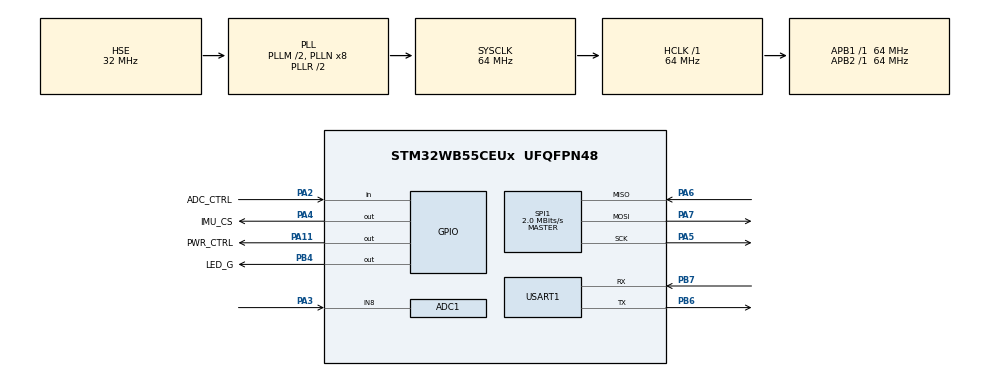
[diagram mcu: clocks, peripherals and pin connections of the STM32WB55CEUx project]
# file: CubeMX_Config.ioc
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ADC1.Channel-0\#ChannelRegularConversion=ADC_CHANNEL_8
ADC1.Channel-3\#ChannelRegularConversion=ADC_CHANNEL_VBAT
ADC1.Channel-4\#ChannelRegularConversion=ADC_CHANNEL_VREFINT
ADC1.ClockPrescaler=ADC_CLOCK_SYNC_PCLK_DIV4
ADC1.EOCSelection=ADC_EOC_SINGLE_CONV
ADC1.NbrOfConversion=3
ADC1.NbrOfConversionFlag=1
ADC1.OffsetNumber-0\#ChannelRegularConversion=ADC_OFFSET_NONE
ADC1.OffsetNumber-3\#ChannelRegularConversion=ADC_OFFSET_NONE
ADC1.OffsetNumber-4\#ChannelRegularConversion=ADC_OFFSET_NONE
ADC1.Overrun=ADC_OVR_DATA_OVERWRITTEN
ADC1.Rank-0\#ChannelRegularConversion=1
ADC1.Rank-3\#ChannelRegularConversion=2
ADC1.Rank-4\#ChannelRegularConversion=3
ADC1.SamplingTime-0\#ChannelRegularConversion=ADC_SAMPLETIME_47CYCLES_5
ADC1.SamplingTime-3\#ChannelRegularConversion=ADC_SAMPLETIME_47CYCLES_5
ADC1.SamplingTime-4\#ChannelRegularConversion=ADC_SAMPLETIME_47CYCLES_5
ADC1.master=1
CRC.InputDataFormat=CRC_INPUTDATA_FORMAT_WORDS
Dma.Request0=USART1_RX
Dma.Request1=USART1_TX
Dma.Request2=SPI1_RX
Dma.Request3=SPI1_TX
Dma.SPI1_RX.2.Direction=DMA_PERIPH_TO_MEMORY
Dma.SPI1_RX.2.EventEnable=DISABLE
Dma.SPI1_RX.2.Instance=DMA1_Channel2
Dma.SPI1_RX.2.MemDataAlignment=DMA_MDATAALIGN_BYTE
Dma.SPI1_RX.2.MemInc=DMA_MINC_ENABLE
Dma.SPI1_RX.2.Mode=DMA_NORMAL
Dma.SPI1_RX.2.PeriphDataAlignment=DMA_PDATAALIGN_BYTE
Dma.SPI1_RX.2.PeriphInc=DMA_PINC_DISABLE
Dma.SPI1_RX.2.Polarity=HAL_DMAMUX_REQ_GEN_RISING
Dma.SPI1_RX.2.Priority=DMA_PRIORITY_HIGH
Dma.SPI1_RX.2.RequestNumber=1
Dma.SPI1_RX.2.SignalID=NONE
Dma.SPI1_RX.2.SyncEnable=DISABLE
Dma.SPI1_RX.2.SyncPolarity=HAL_DMAMUX_SYNC_NO_EVENT
Dma.SPI1_RX.2.SyncRequestNumber=1
Dma.SPI1_RX.2.SyncSignalID=NONE
Dma.SPI1_TX.3.Direction=DMA_MEMORY_TO_PERIPH
Dma.SPI1_TX.3.EventEnable=DISABLE
Dma.SPI1_TX.3.Instance=DMA1_Channel3
Dma.SPI1_TX.3.MemDataAlignment=DMA_MDATAALIGN_BYTE
Dma.SPI1_TX.3.MemInc=DMA_MINC_ENABLE
Dma.SPI1_TX.3.Mode=DMA_NORMAL
Dma.SPI1_TX.3.PeriphDataAlignment=DMA_PDATAALIGN_BYTE
Dma.SPI1_TX.3.PeriphInc=DMA_PINC_DISABLE
Dma.SPI1_TX.3.Polarity=HAL_DMAMUX_REQ_GEN_RISING
Dma.SPI1_TX.3.Priority=DMA_PRIORITY_HIGH
Dma.SPI1_TX.3.RequestNumber=1
Dma.SPI1_TX.3.SignalID=NONE
Dma.SPI1_TX.3.SyncEnable=DISABLE
Dma.SPI1_TX.3.SyncPolarity=HAL_DMAMUX_SYNC_NO_EVENT
Dma.SPI1_TX.3.SyncRequestNumber=1
Dma.SPI1_TX.3.SyncSignalID=NONE
Dma.USART1_RX.0.Direction=DMA_PERIPH_TO_MEMORY
Dma.USART1_RX.0.EventEnable=DISABLE
Dma.USART1_RX.0.Instance=DMA1_Channel1
Dma.USART1_RX.0.MemDataAlignment=DMA_MDATAALIGN_BYTE
Dma.USART1_RX.0.MemInc=DMA_MINC_ENABLE
Dma.USART1_RX.0.Mode=DMA_NORMAL
Dma.USART1_RX.0.PeriphDataAlignment=DMA_PDATAALIGN_BYTE
Dma.USART1_RX.0.PeriphInc=DMA_PINC_DISABLE
Dma.USART1_RX.0.Polarity=HAL_DMAMUX_REQ_GEN_RISING
Dma.USART1_RX.0.Priority=DMA_PRIORITY_VERY_HIGH
Dma.USART1_RX.0.RequestNumber=1
Dma.USART1_RX.0.SignalID=NONE
Dma.USART1_RX.0.SyncEnable=DISABLE
Dma.USART1_RX.0.SyncPolarity=HAL_DMAMUX_SYNC_NO_EVENT
Dma.USART1_RX.0.SyncRequestNumber=1
Dma.USART1_RX.0.SyncSignalID=NONE
Dma.USART1_TX.1.Direction=DMA_MEMORY_TO_PERIPH
Dma.USART1_TX.1.EventEnable=DISABLE
Dma.USART1_TX.1.Instance=DMA1_Channel4
Dma.USART1_TX.1.MemDataAlignment=DMA_MDATAALIGN_BYTE
Dma.USART1_TX.1.MemInc=DMA_MINC_ENABLE
Dma.USART1_TX.1.Mode=DMA_NORMAL
Dma.USART1_TX.1.PeriphDataAlignment=DMA_PDATAALIGN_BYTE
Dma.USART1_TX.1.PeriphInc=DMA_PINC_DISABLE
Dma.USART1_TX.1.Polarity=HAL_DMAMUX_REQ_GEN_RISING
Dma.USART1_TX.1.Priority=DMA_PRIORITY_LOW
Dma.USART1_TX.1.RequestNumber=1
Dma.USART1_TX.1.SignalID=NONE
Dma.USART1_TX.1.SyncEnable=DISABLE
Dma.USART1_TX.1.SyncPolarity=HAL_DMAMUX_SYNC_NO_EVENT
Dma.USART1_TX.1.SyncRequestNumber=1
Dma.USART1_TX.1.SyncSignalID=NONE
LPTIM1.ClockPrescaler=LPTIM_PRESCALER_DIV128
Mcu.Family=STM32WB
Mcu.Name=STM32WB55CEUx
Mcu.Package=UFQFPN48
NVIC.ADC1_IRQn=true\:0\:0\:false\:false\:true\:true\:true\:true
NVIC.DMA1_Channel1_IRQn=true\:0\:0\:false\:false\:true\:false\:true\:true
NVIC.DMA1_Channel2_IRQn=true\:0\:0\:false\:false\:true\:false\:true\:true
NVIC.DMA1_Channel3_IRQn=true\:1\:0\:true\:false\:true\:false\:true\:true
NVIC.DMA1_Channel4_IRQn=true\:2\:0\:true\:false\:true\:false\:true\:true
NVIC.HSEM_IRQn=true\:0\:0\:false\:false\:true\:false\:true\:true
NVIC.IPCC_C1_RX_IRQn=true\:0\:0\:false\:false\:true\:true\:true\:true
NVIC.IPCC_C1_TX_IRQn=true\:0\:0\:false\:false\:true\:true\:true\:true
NVIC.LPTIM1_IRQn=true\:0\:0\:false\:false\:true\:true\:true\:true
NVIC.PriorityGroup=NVIC_PRIORITYGROUP_4
NVIC.USART1_IRQn=true\:0\:0\:false\:false\:true\:true\:true\:true
OSC_IN.Mode=HSE-External-Oscillator
OSC_IN.Signal=RCC_OSC_IN
OSC_OUT.Mode=HSE-External-Oscillator
OSC_OUT.Signal=RCC_OSC_OUT
PA0.GPIO_Label=WKUP_PIN
PA0.Mode=SYS_WakeUp0
PA0.Signal=SYS_WKUP1
PA11.GPIO_Label=PWR_CTRL
PA11.GPIO_PuPd=GPIO_NOPULL
PA11.PinState=GPIO_PIN_SET
PA11.Signal=GPIO_Output
PA13.Mode=Serial_Wire
PA13.Signal=SYS_JTMS-SWDIO
PA14.Mode=Serial_Wire
PA14.Signal=SYS_JTCK-SWCLK
PA2.GPIO_Label=ADC_CTRL
PA2.Signal=GPIO_Input
PA3.Signal=ADCx_IN8
PA4.GPIO_Label=IMU_CS
PA4.PinState=GPIO_PIN_SET
PA4.Signal=GPIO_Output
PA5.GPIO_PuPd=GPIO_PULLUP
PA5.GPIO_Speed=GPIO_SPEED_FREQ_VERY_HIGH
PA5.Mode=Full_Duplex_Master
PA5.Signal=SPI1_SCK
PA6.GPIO_PuPd=GPIO_PULLUP
PA6.GPIO_Speed=GPIO_SPEED_FREQ_VERY_HIGH
PA6.Mode=Full_Duplex_Master
PA6.Signal=SPI1_MISO
PA7.GPIO_PuPd=GPIO_PULLUP
PA7.GPIO_Speed=GPIO_SPEED_FREQ_VERY_HIGH
PA7.Mode=Full_Duplex_Master
PA7.Signal=SPI1_MOSI
PB4.GPIO_Label=LED_G
PB4.Signal=GPIO_Output
PB6.Mode=Asynchronous
PB6.Signal=USART1_TX
PB7.Mode=Asynchronous
PB7.Signal=USART1_RX
PC14-OSC32_IN.Mode=LSE-External-Oscillator
PC14-OSC32_IN.Signal=RCC_OSC32_IN
PC15-OSC32_OUT.Mode=LSE-External-Oscillator
PC15-OSC32_OUT.Signal=RCC_OSC32_OUT
ProjectManager.HeapSize=0x400
ProjectManager.StackSize=0x800
ProjectManager.TargetToolchain=STM32CubeIDE
RCC.ADCFreq_Value=48000000
RCC.AHB2CLKDivider=RCC_SYSCLK_DIV2
RCC.AHBFreq_Value=64000000
RCC.APB1Freq_Value=64000000
RCC.APB1TimFreq_Value=64000000
RCC.APB2Freq_Value=64000000
RCC.APB2TimFreq_Value=64000000
RCC.APB3Freq_Value=16000000
RCC.CortexFreq_Value=64000000
RCC.HCLKFreq_Value=64000000
RCC.HSE_VALUE=32000000
RCC.HSI48_VALUE=48000000
RCC.HSI_VALUE=16000000
RCC.LPTIM1CLockSelection=RCC_LPTIM1CLKSOURCE_LSE
RCC.PLLM=RCC_PLLM_DIV2
RCC.PLLSAI1N=6
RCC.PLLSourceVirtual=RCC_PLLSOURCE_HSE
RCC.RTCClockSelection=RCC_RTCCLKSOURCE_LSE
RCC.SYSCLKFreq_VALUE=64000000
RCC.SYSCLKSource=RCC_SYSCLKSOURCE_PLLCLK
RCC.USBFreq_Value=48000000
RCC.VCOOutputFreq_Value=128000000
RF1.Mode=RF1_Activate
RF1.Signal=RF_RF1
SH.ADCx_IN8.0=ADC1_IN8,IN8-Single-Ended
SPI1.BaudRatePrescaler=SPI_BAUDRATEPRESCALER_32
SPI1.CRCCalculation=SPI_CRCCALCULATION_DISABLE
SPI1.CalculateBaudRate=2.0 MBits/s
SPI1.DataSize=SPI_DATASIZE_8BIT
SPI1.Direction=SPI_DIRECTION_2LINES
SPI1.Mode=SPI_MODE_MASTER
SPI1.NSSPMode=SPI_NSS_PULSE_DISABLE
SPI1.TIMode=SPI_TIMODE_DISABLE
SPI1.VirtualType=VM_MASTER
STM32_WPAN.BLE_STACK=LIGHT
USART1.FIFOMode=FIFOMODE_DISABLE
USART1.VirtualMode-Asynchronous=VM_ASYNC
VP_ADC1_Vbat_Input.Mode=IN-Vbat
VP_ADC1_Vref_Input.Mode=IN-Vrefint
VP_CRC_VS_CRC.Mode=CRC_Activate
VP_HSEM_VS_HSEM.Mode=HSEM_Activate
VP_IPCC_VS_IPCC.Mode=IPCC_Activate
VP_LPTIM1_VS_LPTIM_counterModeInternalClock.Mode=Counts__internal_clock_event_00
VP_RNG_VS_RNG.Mode=RNG_Activate
VP_RTC_VS_RTC_Activate.Mode=RTC_Enabled
VP_SEQUENCER_VS_SEQUENCER.Mode=SEQUENCER_Enabled
VP_STM32_WPAN_VS_BLE_HOST.Mode=STM32_WPAN_Enabled
VP_TINY_LPM_VS_TINY_LPM.Mode=TINY_LPM_Enabled
board=custom

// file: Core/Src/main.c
/* USER CODE BEGIN Header */
/**
  ******************************************************************************
  * @file           : main.c
  * @brief          : Main program body
  ******************************************************************************
  * @attention
  *
  * Copyright (c) 2023 STMicroelectronics.
  * All rights reserved.
  *
  * This software is licensed under terms that can be found in the LICENSE file
  * in the root directory of this software component.
  * If no LICENSE file comes with this software, it is provided AS-IS.
  *
  ******************************************************************************
  */
/* USER CODE END Header */
#include "main.h"

ADC_HandleTypeDef hadc1;

CRC_HandleTypeDef hcrc;

IPCC_HandleTypeDef hipcc;

LPTIM_HandleTypeDef hlptim1;

RNG_HandleTypeDef hrng;

RTC_HandleTypeDef hrtc;

SPI_HandleTypeDef hspi1;
DMA_HandleTypeDef hdma_spi1_rx;
DMA_HandleTypeDef hdma_spi1_tx;

UART_HandleTypeDef huart1;
DMA_HandleTypeDef hdma_usart1_rx;
DMA_HandleTypeDef hdma_usart1_tx;

void SystemClock_Config(void);
void PeriphCommonClock_Config(void);
static void MX_GPIO_Init(void);
static void MX_DMA_Init(void);
static void MX_ADC1_Init(void);
static void MX_CRC_Init(void);
static void MX_IPCC_Init(void);
static void MX_RF_Init(void);
static void MX_RNG_Init(void);
static void MX_SPI1_Init(void);
static void MX_USART1_UART_Init(void);
static void MX_LPTIM1_Init(void);
static void MX_RTC_Init(void);

/* USER CODE BEGIN 0 */

	uint8_t tx_buf[32];
	uint8_t rx_buf[32];
/* USER CODE END 0 */

int main(void)
{

  /* MCU Configuration--------------------------------------------------------*/

  /* Reset of all peripherals, Initializes the Flash interface and the Systick. */
  HAL_Init();
  /* Config code for STM32_WPAN (HSE Tuning must be done before system clock configuration) */
  MX_APPE_Config();

  /* Configure the system clock */
  SystemClock_Config();

/* Configure the peripherals common clocks */
  PeriphCommonClock_Config();

  /* IPCC initialisation */
  MX_IPCC_Init();

  /* Initialize all configured peripherals */
  MX_GPIO_Init();
  MX_DMA_Init();
  MX_ADC1_Init();
  MX_CRC_Init();
  MX_RF_Init();
  MX_RNG_Init();
  MX_SPI1_Init();
  MX_USART1_UART_Init();
  MX_LPTIM1_Init();
  MX_RTC_Init();

  /* Init code for STM32_WPAN */
  MX_APPE_Init();

  /* Infinite loop */
  while (1)
  {
    MX_APPE_Process();

    /* USER CODE BEGIN 3 */
	  memset(tx_buf, 0, 32);
	  tx_buf[0] = 0xA2;

	  HAL_GPIO_WritePin(IMU_CS_GPIO_Port, IMU_CS_Pin, GPIO_PIN_RESET);

	  HAL_SPI_TransmitReceive_DMA(&hspi1, tx_buf, tx_buf, 7);

	  HAL_Delay(50);

	  HAL_GPIO_WritePin(IMU_CS_GPIO_Port, IMU_CS_Pin, GPIO_PIN_SET);

	  HAL_Delay(200);
  }
  /* USER CODE END 3 */
}

void SystemClock_Config(void)
{
  RCC_OscInitTypeDef RCC_OscInitStruct = {0};
  RCC_ClkInitTypeDef RCC_ClkInitStruct = {0};

  /** Configure LSE Drive Capability
  */
  HAL_PWR_EnableBkUpAccess();
  __HAL_RCC_LSEDRIVE_CONFIG(RCC_LSEDRIVE_MEDIUMHIGH);

  /** Configure the main internal regulator output voltage
  */
  __HAL_PWR_VOLTAGESCALING_CONFIG(PWR_REGULATOR_VOLTAGE_SCALE1);

  /** Initializes the RCC Oscillators according to the specified parameters
  * in the RCC_OscInitTypeDef structure.
  */
  RCC_OscInitStruct.OscillatorType = RCC_OSCILLATORTYPE_HSI|RCC_OSCILLATORTYPE_LSI1
                              |RCC_OSCILLATORTYPE_HSE|RCC_OSCILLATORTYPE_LSE;
  RCC_OscInitStruct.HSEState = RCC_HSE_ON;
  RCC_OscInitStruct.LSEState = RCC_LSE_ON;
  RCC_OscInitStruct.HSIState = RCC_HSI_ON;
  RCC_OscInitStruct.HSICalibrationValue = RCC_HSICALIBRATION_DEFAULT;
  RCC_OscInitStruct.LSIState = RCC_LSI_ON;
  RCC_OscInitStruct.PLL.PLLState = RCC_PLL_ON;
  RCC_OscInitStruct.PLL.PLLSource = RCC_PLLSOURCE_HSE;
  RCC_OscInitStruct.PLL.PLLM = RCC_PLLM_DIV2;
  RCC_OscInitStruct.PLL.PLLN = 8;
  RCC_OscInitStruct.PLL.PLLP = RCC_PLLP_DIV2;
  RCC_OscInitStruct.PLL.PLLR = RCC_PLLR_DIV2;
  RCC_OscInitStruct.PLL.PLLQ = RCC_PLLQ_DIV2;
  if (HAL_RCC_OscConfig(&RCC_OscInitStruct) != HAL_OK)
  {
    Error_Handler();
  }

  /** Configure the SYSCLKSource, HCLK, PCLK1 and PCLK2 clocks dividers
  */
  RCC_ClkInitStruct.ClockType = RCC_CLOCKTYPE_HCLK4|RCC_CLOCKTYPE_HCLK2
                              |RCC_CLOCKTYPE_HCLK|RCC_CLOCKTYPE_SYSCLK
                              |RCC_CLOCKTYPE_PCLK1|RCC_CLOCKTYPE_PCLK2;
  RCC_ClkInitStruct.SYSCLKSource = RCC_SYSCLKSOURCE_PLLCLK;
  RCC_ClkInitStruct.AHBCLKDivider = RCC_SYSCLK_DIV1;
  RCC_ClkInitStruct.APB1CLKDivider = RCC_HCLK_DIV1;
  RCC_ClkInitStruct.APB2CLKDivider = RCC_HCLK_DIV1;
  RCC_ClkInitStruct.AHBCLK2Divider = RCC_SYSCLK_DIV2;
  RCC_ClkInitStruct.AHBCLK4Divider = RCC_SYSCLK_DIV1;

  if (HAL_RCC_ClockConfig(&RCC_ClkInitStruct, FLASH_LATENCY_3) != HAL_OK)
  {
    Error_Handler();
  }
}

void PeriphCommonClock_Config(void)
{
  RCC_PeriphCLKInitTypeDef PeriphClkInitStruct = {0};

  /** Initializes the peripherals clock
  */
  PeriphClkInitStruct.PeriphClockSelection = RCC_PERIPHCLK_SMPS|RCC_PERIPHCLK_RFWAKEUP;
  PeriphClkInitStruct.RFWakeUpClockSelection = RCC_RFWKPCLKSOURCE_HSE_DIV1024;
  PeriphClkInitStruct.SmpsClockSelection = RCC_SMPSCLKSOURCE_HSI;
  PeriphClkInitStruct.SmpsDivSelection = RCC_SMPSCLKDIV_RANGE1;

  if (HAL_RCCEx_PeriphCLKConfig(&PeriphClkInitStruct) != HAL_OK)
  {
    Error_Handler();
  }
}

static void MX_ADC1_Init(void)
{

  ADC_ChannelConfTypeDef sConfig = {0};

  /** Common config
  */
  hadc1.Instance = ADC1;
  hadc1.Init.ClockPrescaler = ADC_CLOCK_SYNC_PCLK_DIV4;
  hadc1.Init.Resolution = ADC_RESOLUTION_12B;
  hadc1.Init.DataAlign = ADC_DATAALIGN_RIGHT;
  hadc1.Init.ScanConvMode = ADC_SCAN_ENABLE;
  hadc1.Init.EOCSelection = ADC_EOC_SINGLE_CONV;
  hadc1.Init.LowPowerAutoWait = DISABLE;
  hadc1.Init.ContinuousConvMode = DISABLE;
  hadc1.Init.NbrOfConversion = 3;
  hadc1.Init.DiscontinuousConvMode = DISABLE;
  hadc1.Init.ExternalTrigConv = ADC_SOFTWARE_START;
  hadc1.Init.ExternalTrigConvEdge = ADC_EXTERNALTRIGCONVEDGE_NONE;
  hadc1.Init.DMAContinuousRequests = DISABLE;
  hadc1.Init.Overrun = ADC_OVR_DATA_OVERWRITTEN;
  hadc1.Init.OversamplingMode = DISABLE;
  if (HAL_ADC_Init(&hadc1) != HAL_OK)
  {
    Error_Handler();
  }

  /** Configure Regular Channel
  */
  sConfig.Channel = ADC_CHANNEL_8;
  sConfig.Rank = ADC_REGULAR_RANK_1;
  sConfig.SamplingTime = ADC_SAMPLETIME_47CYCLES_5;
  sConfig.SingleDiff = ADC_SINGLE_ENDED;
  sConfig.OffsetNumber = ADC_OFFSET_NONE;
  sConfig.Offset = 0;
  if (HAL_ADC_ConfigChannel(&hadc1, &sConfig) != HAL_OK)
  {
    Error_Handler();
  }

  /** Configure Regular Channel
  */
  sConfig.Channel = ADC_CHANNEL_VBAT;
  sConfig.Rank = ADC_REGULAR_RANK_2;
  if (HAL_ADC_ConfigChannel(&hadc1, &sConfig) != HAL_OK)
  {
    Error_Handler();
  }

  /** Configure Regular Channel
  */
  sConfig.Channel = ADC_CHANNEL_VREFINT;
  sConfig.Rank = ADC_REGULAR_RANK_3;
  if (HAL_ADC_ConfigChannel(&hadc1, &sConfig) != HAL_OK)
  {
    Error_Handler();
  }

}

static void MX_CRC_Init(void)
{

  hcrc.Instance = CRC;
  hcrc.Init.DefaultPolynomialUse = DEFAULT_POLYNOMIAL_ENABLE;
  hcrc.Init.DefaultInitValueUse = DEFAULT_INIT_VALUE_ENABLE;
  hcrc.Init.InputDataInversionMode = CRC_INPUTDATA_INVERSION_NONE;
  hcrc.Init.OutputDataInversionMode = CRC_OUTPUTDATA_INVERSION_DISABLE;
  hcrc.InputDataFormat = CRC_INPUTDATA_FORMAT_WORDS;
  if (HAL_CRC_Init(&hcrc) != HAL_OK)
  {
    Error_Handler();
  }

}

static void MX_IPCC_Init(void)
{

  hipcc.Instance = IPCC;
  if (HAL_IPCC_Init(&hipcc) != HAL_OK)
  {
    Error_Handler();
  }

}

static void MX_LPTIM1_Init(void)
{

  hlptim1.Instance = LPTIM1;
  hlptim1.Init.Clock.Source = LPTIM_CLOCKSOURCE_APBCLOCK_LPOSC;
  hlptim1.Init.Clock.Prescaler = LPTIM_PRESCALER_DIV128;
  hlptim1.Init.Trigger.Source = LPTIM_TRIGSOURCE_SOFTWARE;
  hlptim1.Init.OutputPolarity = LPTIM_OUTPUTPOLARITY_HIGH;
  hlptim1.Init.UpdateMode = LPTIM_UPDATE_IMMEDIATE;
  hlptim1.Init.CounterSource = LPTIM_COUNTERSOURCE_INTERNAL;
  hlptim1.Init.Input1Source = LPTIM_INPUT1SOURCE_GPIO;
  hlptim1.Init.Input2Source = LPTIM_INPUT2SOURCE_GPIO;
  if (HAL_LPTIM_Init(&hlptim1) != HAL_OK)
  {
    Error_Handler();
  }

}

static void MX_RF_Init(void)
{

}

static void MX_RNG_Init(void)
{

  hrng.Instance = RNG;
  hrng.Init.ClockErrorDetection = RNG_CED_ENABLE;
  if (HAL_RNG_Init(&hrng) != HAL_OK)
  {
    Error_Handler();
  }

}

static void MX_RTC_Init(void)
{

  /** Initialize RTC Only
  */
  hrtc.Instance = RTC;
  hrtc.Init.HourFormat = RTC_HOURFORMAT_24;
  hrtc.Init.AsynchPrediv = CFG_RTC_ASYNCH_PRESCALER;
  hrtc.Init.SynchPrediv = CFG_RTC_SYNCH_PRESCALER;
  hrtc.Init.OutPut = RTC_OUTPUT_DISABLE;
  hrtc.Init.OutPutPolarity = RTC_OUTPUT_POLARITY_HIGH;
  hrtc.Init.OutPutType = RTC_OUTPUT_TYPE_OPENDRAIN;
  hrtc.Init.OutPutRemap = RTC_OUTPUT_REMAP_NONE;
  if (HAL_RTC_Init(&hrtc) != HAL_OK)
  {
    Error_Handler();
  }

}

static void MX_SPI1_Init(void)
{

  /* SPI1 parameter configuration*/
  hspi1.Instance = SPI1;
  hspi1.Init.Mode = SPI_MODE_MASTER;
  hspi1.Init.Direction = SPI_DIRECTION_2LINES;
  hspi1.Init.DataSize = SPI_DATASIZE_8BIT;
  hspi1.Init.CLKPolarity = SPI_POLARITY_LOW;
  hspi1.Init.CLKPhase = SPI_PHASE_1EDGE;
  hspi1.Init.NSS = SPI_NSS_SOFT;
  hspi1.Init.BaudRatePrescaler = SPI_BAUDRATEPRESCALER_32;
  hspi1.Init.FirstBit = SPI_FIRSTBIT_MSB;
  hspi1.Init.TIMode = SPI_TIMODE_DISABLE;
  hspi1.Init.CRCCalculation = SPI_CRCCALCULATION_DISABLE;
  hspi1.Init.CRCPolynomial = 7;
  hspi1.Init.CRCLength = SPI_CRC_LENGTH_DATASIZE;
  hspi1.Init.NSSPMode = SPI_NSS_PULSE_DISABLE;
  if (HAL_SPI_Init(&hspi1) != HAL_OK)
  {
    Error_Handler();
  }

}

static void MX_USART1_UART_Init(void)
{

  huart1.Instance = USART1;
  huart1.Init.BaudRate = 115200;
  huart1.Init.WordLength = UART_WORDLENGTH_8B;
  huart1.Init.StopBits = UART_STOPBITS_1;
  huart1.Init.Parity = UART_PARITY_NONE;
  huart1.Init.Mode = UART_MODE_TX_RX;
  huart1.Init.HwFlowCtl = UART_HWCONTROL_NONE;
  huart1.Init.OverSampling = UART_OVERSAMPLING_16;
  huart1.Init.OneBitSampling = UART_ONE_BIT_SAMPLE_DISABLE;
  huart1.Init.ClockPrescaler = UART_PRESCALER_DIV1;
  huart1.AdvancedInit.AdvFeatureInit = UART_ADVFEATURE_NO_INIT;
  if (HAL_UART_Init(&huart1) != HAL_OK)
  {
    Error_Handler();
  }
  if (HAL_UARTEx_SetTxFifoThreshold(&huart1, UART_TXFIFO_THRESHOLD_1_8) != HAL_OK)
  {
    Error_Handler();
  }
  if (HAL_UARTEx_SetRxFifoThreshold(&huart1, UART_RXFIFO_THRESHOLD_1_8) != HAL_OK)
  {
    Error_Handler();
  }
  if (HAL_UARTEx_DisableFifoMode(&huart1) != HAL_OK)
  {
    Error_Handler();
  }

}

static void MX_DMA_Init(void)
{

  /* DMA controller clock enable */
  __HAL_RCC_DMAMUX1_CLK_ENABLE();
  __HAL_RCC_DMA1_CLK_ENABLE();

  /* DMA interrupt init */
  /* DMA1_Channel1_IRQn interrupt configuration */
  HAL_NVIC_SetPriority(DMA1_Channel1_IRQn, 0, 0);
  HAL_NVIC_EnableIRQ(DMA1_Channel1_IRQn);
  /* DMA1_Channel2_IRQn interrupt configuration */
  HAL_NVIC_SetPriority(DMA1_Channel2_IRQn, 0, 0);
  HAL_NVIC_EnableIRQ(DMA1_Channel2_IRQn);
  /* DMA1_Channel3_IRQn interrupt configuration */
  HAL_NVIC_SetPriority(DMA1_Channel3_IRQn, 1, 0);
  HAL_NVIC_EnableIRQ(DMA1_Channel3_IRQn);
  /* DMA1_Channel4_IRQn interrupt configuration */
  HAL_NVIC_SetPriority(DMA1_Channel4_IRQn, 2, 0);
  HAL_NVIC_EnableIRQ(DMA1_Channel4_IRQn);

}

static void MX_GPIO_Init(void)
{
  GPIO_InitTypeDef GPIO_InitStruct = {0};

  /* GPIO Ports Clock Enable */
  __HAL_RCC_GPIOC_CLK_ENABLE();
  __HAL_RCC_GPIOH_CLK_ENABLE();
  __HAL_RCC_GPIOB_CLK_ENABLE();
  __HAL_RCC_GPIOA_CLK_ENABLE();
  __HAL_RCC_GPIOE_CLK_ENABLE();

  /*Configure GPIO pin Output Level */
  HAL_GPIO_WritePin(GPIOA, IMU_CS_Pin|PWR_CTRL_Pin, GPIO_PIN_SET);

  /*Configure GPIO pin Output Level */
  HAL_GPIO_WritePin(LED_G_GPIO_Port, LED_G_Pin, GPIO_PIN_RESET);

  /*Configure GPIO pin : PH3 */
  GPIO_InitStruct.Pin = GPIO_PIN_3;
  GPIO_InitStruct.Mode = GPIO_MODE_ANALOG;
  GPIO_InitStruct.Pull = GPIO_NOPULL;
  HAL_GPIO_Init(GPIOH, &GPIO_InitStruct);

  /*Configure GPIO pins : PB8 PB9 PB2 PB0
                           PB1 PB3 PB5 */
  GPIO_InitStruct.Pin = GPIO_PIN_8|GPIO_PIN_9|GPIO_PIN_2|GPIO_PIN_0
                          |GPIO_PIN_1|GPIO_PIN_3|GPIO_PIN_5;
  GPIO_InitStruct.Mode = GPIO_MODE_ANALOG;
  GPIO_InitStruct.Pull = GPIO_NOPULL;
  HAL_GPIO_Init(GPIOB, &GPIO_InitStruct);

  /*Configure GPIO pins : PA1 PA8 PA9 PA10
                           PA12 PA15 */
  GPIO_InitStruct.Pin = GPIO_PIN_1|GPIO_PIN_8|GPIO_PIN_9|GPIO_PIN_10
                          |GPIO_PIN_12|GPIO_PIN_15;
  GPIO_InitStruct.Mode = GPIO_MODE_ANALOG;
  GPIO_InitStruct.Pull = GPIO_NOPULL;
  HAL_GPIO_Init(GPIOA, &GPIO_InitStruct);

  /*Configure GPIO pin : ADC_CTRL_Pin */
  GPIO_InitStruct.Pin = ADC_CTRL_Pin;
  GPIO_InitStruct.Mode = GPIO_MODE_INPUT;
  GPIO_InitStruct.Pull = GPIO_NOPULL;
  HAL_GPIO_Init(ADC_CTRL_GPIO_Port, &GPIO_InitStruct);

  /*Configure GPIO pins : IMU_CS_Pin PWR_CTRL_Pin */
  GPIO_InitStruct.Pin = IMU_CS_Pin|PWR_CTRL_Pin;
  GPIO_InitStruct.Mode = GPIO_MODE_OUTPUT_PP;
  GPIO_InitStruct.Pull = GPIO_NOPULL;
  GPIO_InitStruct.Speed = GPIO_SPEED_FREQ_LOW;
  HAL_GPIO_Init(GPIOA, &GPIO_InitStruct);

  /*Configure GPIO pin : PE4 */
  GPIO_InitStruct.Pin = GPIO_PIN_4;
  GPIO_InitStruct.Mode = GPIO_MODE_ANALOG;
  GPIO_InitStruct.Pull = GPIO_NOPULL;
  HAL_GPIO_Init(GPIOE, &GPIO_InitStruct);

  /*Configure GPIO pin : LED_G_Pin */
  GPIO_InitStruct.Pin = LED_G_Pin;
  GPIO_InitStruct.Mode = GPIO_MODE_OUTPUT_PP;
  GPIO_InitStruct.Pull = GPIO_NOPULL;
  GPIO_InitStruct.Speed = GPIO_SPEED_FREQ_LOW;
  HAL_GPIO_Init(LED_G_GPIO_Port, &GPIO_InitStruct);

}

void Error_Handler(void)
{
  __disable_irq();
  while (1)
  {
  }
}
